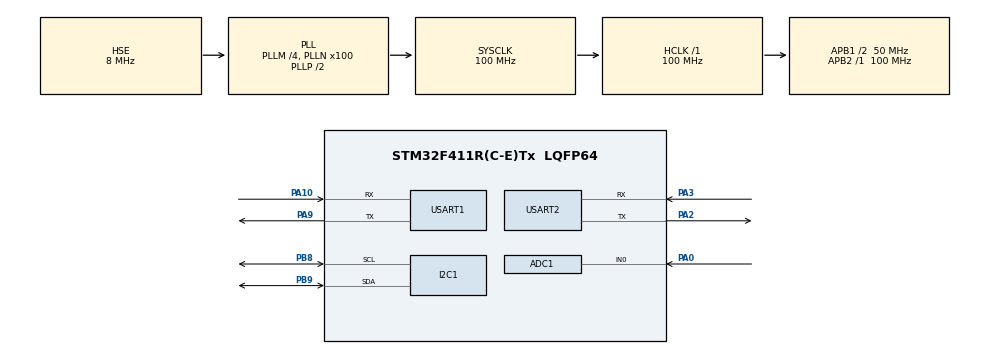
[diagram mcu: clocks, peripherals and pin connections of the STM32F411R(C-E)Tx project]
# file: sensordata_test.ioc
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ADC1.Channel-0\#ChannelRegularConversion=ADC_CHANNEL_0
ADC1.NbrOfConversionFlag=1
ADC1.Rank-0\#ChannelRegularConversion=1
ADC1.SamplingTime-0\#ChannelRegularConversion=ADC_SAMPLETIME_3CYCLES
ADC1.master=1
Dma.Request0=USART2_RX
Dma.Request1=USART2_TX
Dma.Request2=USART1_TX
Dma.USART1_TX.2.Direction=DMA_MEMORY_TO_PERIPH
Dma.USART1_TX.2.FIFOMode=DMA_FIFOMODE_DISABLE
Dma.USART1_TX.2.Instance=DMA2_Stream7
Dma.USART1_TX.2.MemDataAlignment=DMA_MDATAALIGN_BYTE
Dma.USART1_TX.2.MemInc=DMA_MINC_ENABLE
Dma.USART1_TX.2.Mode=DMA_NORMAL
Dma.USART1_TX.2.PeriphDataAlignment=DMA_PDATAALIGN_BYTE
Dma.USART1_TX.2.PeriphInc=DMA_PINC_DISABLE
Dma.USART1_TX.2.Priority=DMA_PRIORITY_LOW
Dma.USART2_RX.0.Direction=DMA_PERIPH_TO_MEMORY
Dma.USART2_RX.0.FIFOMode=DMA_FIFOMODE_DISABLE
Dma.USART2_RX.0.Instance=DMA1_Stream5
Dma.USART2_RX.0.MemDataAlignment=DMA_MDATAALIGN_BYTE
Dma.USART2_RX.0.MemInc=DMA_MINC_ENABLE
Dma.USART2_RX.0.Mode=DMA_NORMAL
Dma.USART2_RX.0.PeriphDataAlignment=DMA_PDATAALIGN_BYTE
Dma.USART2_RX.0.PeriphInc=DMA_PINC_DISABLE
Dma.USART2_RX.0.Priority=DMA_PRIORITY_LOW
Dma.USART2_TX.1.Direction=DMA_MEMORY_TO_PERIPH
Dma.USART2_TX.1.FIFOMode=DMA_FIFOMODE_DISABLE
Dma.USART2_TX.1.Instance=DMA1_Stream6
Dma.USART2_TX.1.MemDataAlignment=DMA_MDATAALIGN_BYTE
Dma.USART2_TX.1.MemInc=DMA_MINC_ENABLE
Dma.USART2_TX.1.Mode=DMA_NORMAL
Dma.USART2_TX.1.PeriphDataAlignment=DMA_PDATAALIGN_BYTE
Dma.USART2_TX.1.PeriphInc=DMA_PINC_DISABLE
Dma.USART2_TX.1.Priority=DMA_PRIORITY_LOW
Mcu.Family=STM32F4
Mcu.Name=STM32F411R(C-E)Tx
Mcu.Package=LQFP64
NVIC.DMA1_Stream5_IRQn=true\:0\:0\:false\:false\:true\:false\:true\:true
NVIC.DMA1_Stream6_IRQn=true\:0\:0\:false\:false\:true\:false\:true\:true
NVIC.DMA2_Stream7_IRQn=true\:0\:0\:false\:false\:true\:false\:true\:true
NVIC.I2C1_ER_IRQn=true\:0\:0\:false\:false\:true\:true\:true\:true
NVIC.I2C1_EV_IRQn=true\:0\:0\:false\:false\:true\:true\:true\:true
NVIC.PriorityGroup=NVIC_PRIORITYGROUP_4
NVIC.TIM3_IRQn=true\:0\:0\:false\:false\:true\:true\:true\:true
NVIC.USART1_IRQn=true\:0\:0\:false\:false\:true\:true\:true\:true
NVIC.USART2_IRQn=true\:0\:0\:false\:false\:true\:true\:true\:true
PA0-WKUP.Signal=ADCx_IN0
PA10.Mode=Asynchronous
PA10.Signal=USART1_RX
PA2.Mode=Asynchronous
PA2.Signal=USART2_TX
PA3.Mode=Asynchronous
PA3.Signal=USART2_RX
PA9.Mode=Asynchronous
PA9.Signal=USART1_TX
PB8.Mode=I2C
PB8.Signal=I2C1_SCL
PB9.Mode=I2C
PB9.Signal=I2C1_SDA
PH0\ -\ OSC_IN.Mode=HSE-External-Oscillator
PH0\ -\ OSC_IN.Signal=RCC_OSC_IN
PH1\ -\ OSC_OUT.Mode=HSE-External-Oscillator
PH1\ -\ OSC_OUT.Signal=RCC_OSC_OUT
ProjectManager.HeapSize=0x200
ProjectManager.StackSize=0x400
ProjectManager.TargetToolchain=STM32CubeIDE
RCC.48MHZClocksFreq_Value=50000000
RCC.AHBFreq_Value=100000000
RCC.APB1CLKDivider=RCC_HCLK_DIV2
RCC.APB1Freq_Value=50000000
RCC.APB1TimFreq_Value=100000000
RCC.APB2Freq_Value=100000000
RCC.APB2TimFreq_Value=100000000
RCC.CortexFreq_Value=100000000
RCC.HCLKFreq_Value=100000000
RCC.HSE_VALUE=8000000
RCC.HSI_VALUE=16000000
RCC.LSE_VALUE=32768
RCC.PLLM=4
RCC.PLLN=100
RCC.PLLSourceVirtual=RCC_PLLSOURCE_HSE
RCC.SYSCLKFreq_VALUE=100000000
RCC.SYSCLKSource=RCC_SYSCLKSOURCE_PLLCLK
RCC.VCOOutputFreq_Value=200000000
SH.ADCx_IN0.0=ADC1_IN0,IN0
TIM3.Period=1000-1
TIM3.Prescaler=84-1
USART1.VirtualMode=VM_ASYNC
USART2.VirtualMode=VM_ASYNC
VP_RTC_VS_RTC_Activate.Mode=RTC_Enabled
VP_RTC_VS_RTC_Calendar.Mode=RTC_Calendar
VP_TIM3_VS_ClockSourceINT.Mode=Internal
board=custom

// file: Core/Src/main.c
/* USER CODE BEGIN Header */
/**
  ******************************************************************************
  * @file           : main.c
  * @brief          : Main program body
  ******************************************************************************
  * @attention
  *
  * Copyright (c) 2026 STMicroelectronics.
  * All rights reserved.
  *
  * This software is licensed under terms that can be found in the LICENSE file
  * in the root directory of this software component.
  * If no LICENSE file comes with this software, it is provided AS-IS.
  *
  ******************************************************************************
  */
/* USER CODE END Header */
#include "main.h"

/* USER CODE BEGIN Includes */
#include "../App/ap_main.h"

/* USER CODE END Includes */

ADC_HandleTypeDef hadc1;

I2C_HandleTypeDef hi2c1;

RTC_HandleTypeDef hrtc;

TIM_HandleTypeDef htim3;

UART_HandleTypeDef huart1;
UART_HandleTypeDef huart2;
DMA_HandleTypeDef hdma_usart1_tx;
DMA_HandleTypeDef hdma_usart2_rx;
DMA_HandleTypeDef hdma_usart2_tx;

void SystemClock_Config(void);
static void MX_GPIO_Init(void);
static void MX_DMA_Init(void);
static void MX_I2C1_Init(void);
static void MX_USART2_UART_Init(void);
static void MX_ADC1_Init(void);
static void MX_TIM3_Init(void);
static void MX_RTC_Init(void);
static void MX_USART1_UART_Init(void);

int main(void)
{

  /* MCU Configuration--------------------------------------------------------*/

  /* Reset of all peripherals, Initializes the Flash interface and the Systick. */
  HAL_Init();

  /* Configure the system clock */
  SystemClock_Config();

  /* Initialize all configured peripherals */
  MX_GPIO_Init();
  MX_DMA_Init();
  MX_I2C1_Init();
  MX_USART2_UART_Init();
  MX_ADC1_Init();
  MX_TIM3_Init();
  MX_RTC_Init();
  MX_USART1_UART_Init();
  /* USER CODE BEGIN 2 */
  ap_Init();
  /* USER CODE END 2 */

  /* Infinite loop */
  while (1)
  {

    /* USER CODE BEGIN 3 */
	  ap_exe();
  }
  /* USER CODE END 3 */
}

void SystemClock_Config(void)
{
  RCC_OscInitTypeDef RCC_OscInitStruct = {0};
  RCC_ClkInitTypeDef RCC_ClkInitStruct = {0};

  /** Configure the main internal regulator output voltage
  */
  __HAL_RCC_PWR_CLK_ENABLE();
  __HAL_PWR_VOLTAGESCALING_CONFIG(PWR_REGULATOR_VOLTAGE_SCALE1);

  /** Initializes the RCC Oscillators according to the specified parameters
  * in the RCC_OscInitTypeDef structure.
  */
  RCC_OscInitStruct.OscillatorType = RCC_OSCILLATORTYPE_LSI|RCC_OSCILLATORTYPE_HSE;
  RCC_OscInitStruct.HSEState = RCC_HSE_ON;
  RCC_OscInitStruct.LSIState = RCC_LSI_ON;
  RCC_OscInitStruct.PLL.PLLState = RCC_PLL_ON;
  RCC_OscInitStruct.PLL.PLLSource = RCC_PLLSOURCE_HSE;
  RCC_OscInitStruct.PLL.PLLM = 4;
  RCC_OscInitStruct.PLL.PLLN = 100;
  RCC_OscInitStruct.PLL.PLLP = RCC_PLLP_DIV2;
  RCC_OscInitStruct.PLL.PLLQ = 4;
  if (HAL_RCC_OscConfig(&RCC_OscInitStruct) != HAL_OK)
  {
    Error_Handler();
  }

  /** Initializes the CPU, AHB and APB buses clocks
  */
  RCC_ClkInitStruct.ClockType = RCC_CLOCKTYPE_HCLK|RCC_CLOCKTYPE_SYSCLK
                              |RCC_CLOCKTYPE_PCLK1|RCC_CLOCKTYPE_PCLK2;
  RCC_ClkInitStruct.SYSCLKSource = RCC_SYSCLKSOURCE_PLLCLK;
  RCC_ClkInitStruct.AHBCLKDivider = RCC_SYSCLK_DIV1;
  RCC_ClkInitStruct.APB1CLKDivider = RCC_HCLK_DIV2;
  RCC_ClkInitStruct.APB2CLKDivider = RCC_HCLK_DIV1;

  if (HAL_RCC_ClockConfig(&RCC_ClkInitStruct, FLASH_LATENCY_3) != HAL_OK)
  {
    Error_Handler();
  }
}

static void MX_ADC1_Init(void)
{

  ADC_ChannelConfTypeDef sConfig = {0};

  /** Configure the global features of the ADC (Clock, Resolution, Data Alignment and number of conversion)
  */
  hadc1.Instance = ADC1;
  hadc1.Init.ClockPrescaler = ADC_CLOCK_SYNC_PCLK_DIV4;
  hadc1.Init.Resolution = ADC_RESOLUTION_12B;
  hadc1.Init.ScanConvMode = DISABLE;
  hadc1.Init.ContinuousConvMode = DISABLE;
  hadc1.Init.DiscontinuousConvMode = DISABLE;
  hadc1.Init.ExternalTrigConvEdge = ADC_EXTERNALTRIGCONVEDGE_NONE;
  hadc1.Init.ExternalTrigConv = ADC_SOFTWARE_START;
  hadc1.Init.DataAlign = ADC_DATAALIGN_RIGHT;
  hadc1.Init.NbrOfConversion = 1;
  hadc1.Init.DMAContinuousRequests = DISABLE;
  hadc1.Init.EOCSelection = ADC_EOC_SINGLE_CONV;
  if (HAL_ADC_Init(&hadc1) != HAL_OK)
  {
    Error_Handler();
  }

  /** Configure for the selected ADC regular channel its corresponding rank in the sequencer and its sample time.
  */
  sConfig.Channel = ADC_CHANNEL_0;
  sConfig.Rank = 1;
  sConfig.SamplingTime = ADC_SAMPLETIME_3CYCLES;
  if (HAL_ADC_ConfigChannel(&hadc1, &sConfig) != HAL_OK)
  {
    Error_Handler();
  }

}

static void MX_I2C1_Init(void)
{

  hi2c1.Instance = I2C1;
  hi2c1.Init.ClockSpeed = 100000;
  hi2c1.Init.DutyCycle = I2C_DUTYCYCLE_2;
  hi2c1.Init.OwnAddress1 = 0;
  hi2c1.Init.AddressingMode = I2C_ADDRESSINGMODE_7BIT;
  hi2c1.Init.DualAddressMode = I2C_DUALADDRESS_DISABLE;
  hi2c1.Init.OwnAddress2 = 0;
  hi2c1.Init.GeneralCallMode = I2C_GENERALCALL_DISABLE;
  hi2c1.Init.NoStretchMode = I2C_NOSTRETCH_DISABLE;
  if (HAL_I2C_Init(&hi2c1) != HAL_OK)
  {
    Error_Handler();
  }

}

static void MX_RTC_Init(void)
{

  RTC_TimeTypeDef sTime = {0};
  RTC_DateTypeDef sDate = {0};

  /** Initialize RTC Only
  */
  hrtc.Instance = RTC;
  hrtc.Init.HourFormat = RTC_HOURFORMAT_24;
  hrtc.Init.AsynchPrediv = 127;
  hrtc.Init.SynchPrediv = 255;
  hrtc.Init.OutPut = RTC_OUTPUT_DISABLE;
  hrtc.Init.OutPutPolarity = RTC_OUTPUT_POLARITY_HIGH;
  hrtc.Init.OutPutType = RTC_OUTPUT_TYPE_OPENDRAIN;
  if (HAL_RTC_Init(&hrtc) != HAL_OK)
  {
    Error_Handler();
  }

  /** Initialize RTC and set the Time and Date
  */
  sTime.Hours = 0x0;
  sTime.Minutes = 0x0;
  sTime.Seconds = 0x0;
  sTime.DayLightSaving = RTC_DAYLIGHTSAVING_NONE;
  sTime.StoreOperation = RTC_STOREOPERATION_RESET;
  if (HAL_RTC_SetTime(&hrtc, &sTime, RTC_FORMAT_BCD) != HAL_OK)
  {
    Error_Handler();
  }
  sDate.WeekDay = RTC_WEEKDAY_MONDAY;
  sDate.Month = RTC_MONTH_JANUARY;
  sDate.Date = 0x1;
  sDate.Year = 0x0;

  if (HAL_RTC_SetDate(&hrtc, &sDate, RTC_FORMAT_BCD) != HAL_OK)
  {
    Error_Handler();
  }

}

static void MX_TIM3_Init(void)
{

  TIM_ClockConfigTypeDef sClockSourceConfig = {0};
  TIM_MasterConfigTypeDef sMasterConfig = {0};

  htim3.Instance = TIM3;
  htim3.Init.Prescaler = 84-1;
  htim3.Init.CounterMode = TIM_COUNTERMODE_UP;
  htim3.Init.Period = 1000-1;
  htim3.Init.ClockDivision = TIM_CLOCKDIVISION_DIV1;
  htim3.Init.AutoReloadPreload = TIM_AUTORELOAD_PRELOAD_DISABLE;
  if (HAL_TIM_Base_Init(&htim3) != HAL_OK)
  {
    Error_Handler();
  }
  sClockSourceConfig.ClockSource = TIM_CLOCKSOURCE_INTERNAL;
  if (HAL_TIM_ConfigClockSource(&htim3, &sClockSourceConfig) != HAL_OK)
  {
    Error_Handler();
  }
  sMasterConfig.MasterOutputTrigger = TIM_TRGO_RESET;
  sMasterConfig.MasterSlaveMode = TIM_MASTERSLAVEMODE_DISABLE;
  if (HAL_TIMEx_MasterConfigSynchronization(&htim3, &sMasterConfig) != HAL_OK)
  {
    Error_Handler();
  }

}

static void MX_USART1_UART_Init(void)
{

  huart1.Instance = USART1;
  huart1.Init.BaudRate = 115200;
  huart1.Init.WordLength = UART_WORDLENGTH_8B;
  huart1.Init.StopBits = UART_STOPBITS_1;
  huart1.Init.Parity = UART_PARITY_NONE;
  huart1.Init.Mode = UART_MODE_TX_RX;
  huart1.Init.HwFlowCtl = UART_HWCONTROL_NONE;
  huart1.Init.OverSampling = UART_OVERSAMPLING_16;
  if (HAL_UART_Init(&huart1) != HAL_OK)
  {
    Error_Handler();
  }

}

static void MX_USART2_UART_Init(void)
{

  huart2.Instance = USART2;
  huart2.Init.BaudRate = 115200;
  huart2.Init.WordLength = UART_WORDLENGTH_8B;
  huart2.Init.StopBits = UART_STOPBITS_1;
  huart2.Init.Parity = UART_PARITY_NONE;
  huart2.Init.Mode = UART_MODE_TX_RX;
  huart2.Init.HwFlowCtl = UART_HWCONTROL_NONE;
  huart2.Init.OverSampling = UART_OVERSAMPLING_16;
  if (HAL_UART_Init(&huart2) != HAL_OK)
  {
    Error_Handler();
  }

}

static void MX_DMA_Init(void)
{

  /* DMA controller clock enable */
  __HAL_RCC_DMA1_CLK_ENABLE();
  __HAL_RCC_DMA2_CLK_ENABLE();

  /* DMA interrupt init */
  /* DMA1_Stream5_IRQn interrupt configuration */
  HAL_NVIC_SetPriority(DMA1_Stream5_IRQn, 0, 0);
  HAL_NVIC_EnableIRQ(DMA1_Stream5_IRQn);
  /* DMA1_Stream6_IRQn interrupt configuration */
  HAL_NVIC_SetPriority(DMA1_Stream6_IRQn, 0, 0);
  HAL_NVIC_EnableIRQ(DMA1_Stream6_IRQn);
  /* DMA2_Stream7_IRQn interrupt configuration */
  HAL_NVIC_SetPriority(DMA2_Stream7_IRQn, 0, 0);
  HAL_NVIC_EnableIRQ(DMA2_Stream7_IRQn);

}

static void MX_GPIO_Init(void)
{

  /* GPIO Ports Clock Enable */
  __HAL_RCC_GPIOH_CLK_ENABLE();
  __HAL_RCC_GPIOA_CLK_ENABLE();
  __HAL_RCC_GPIOB_CLK_ENABLE();

}

void Error_Handler(void)
{
  __disable_irq();
  while (1)
  {
  }
}
